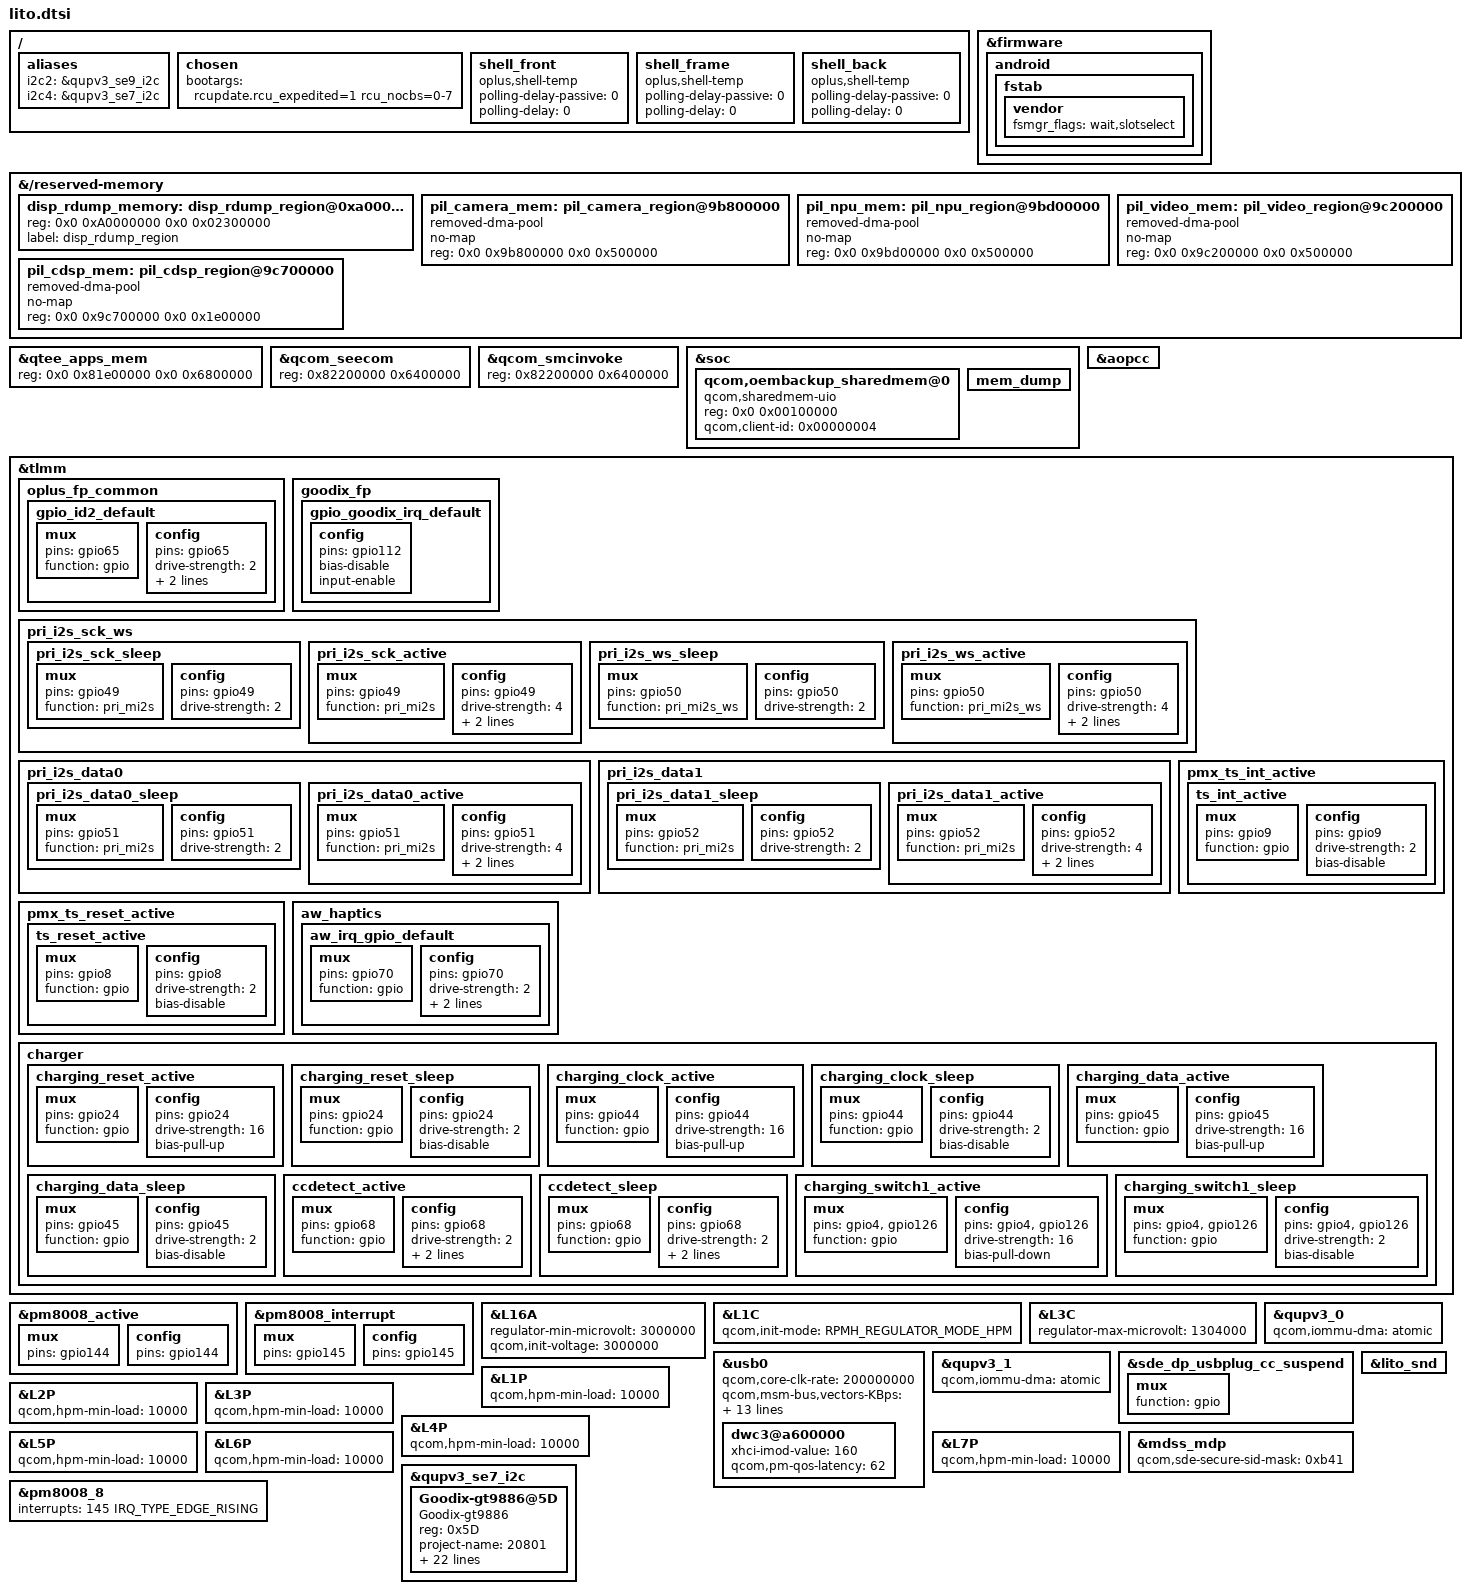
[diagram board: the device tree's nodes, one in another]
// lito.dtsi - OnePlus Nord (20801) delta on top of ../qcom/lito.dtsi
/ {
	aliases {
		i2c2 = &qupv3_se9_i2c;
		i2c4 = &qupv3_se7_i2c;
	};

	chosen {
		bootargs = "rcupdate.rcu_expedited=1 rcu_nocbs=0-7";
	};

	// lito-thermal.dtsi
	shell_front {
		polling-delay-passive = <0>;
		polling-delay = <0>;
		compatible = "oplus,shell-temp";
	};

	shell_frame {
		polling-delay-passive = <0>;
		polling-delay = <0>;
		compatible = "oplus,shell-temp";
	};

	shell_back {
		polling-delay-passive = <0>;
		polling-delay = <0>;
		compatible = "oplus,shell-temp";
	};
};

&firmware {
	android {
		fstab {
			vendor {
				fsmgr_flags = "wait,slotselect";
			};
		};
	};
};

reserved_memory: &{/reserved-memory} {
	disp_rdump_memory: disp_rdump_region@0xa0000000 {
		reg = <0x0 0xA0000000 0x0 0x02300000>;
		label = "disp_rdump_region";
	};
};

/delete-node/ &reserved_xbl_uefi_log;
/delete-node/ &pil_camera_mem;
/delete-node/ &pil_npu_mem;
/delete-node/ &pil_video_mem;
/delete-node/ &pil_cdsp_mem;

&reserved_memory {
	pil_camera_mem: pil_camera_region@9b800000 {
		compatible = "removed-dma-pool";
		no-map;
		reg = <0x0 0x9b800000 0x0 0x500000>;
	};

	pil_npu_mem: pil_npu_region@9bd00000 {
		compatible = "removed-dma-pool";
		no-map;
		reg = <0x0 0x9bd00000 0x0 0x500000>;
	};

	pil_video_mem: pil_video_region@9c200000 {
		compatible = "removed-dma-pool";
		no-map;
		reg = <0x0 0x9c200000 0x0 0x500000>;
	};

	pil_cdsp_mem: pil_cdsp_region@9c700000 {
		compatible = "removed-dma-pool";
		no-map;
		reg = <0x0 0x9c700000 0x0 0x1e00000>;
	};
};

&qtee_apps_mem {
	reg = <0x0 0x81e00000 0x0 0x6800000>;
};

&qcom_seecom {
	reg = <0x82200000 0x6400000>;
};

&qcom_smcinvoke {
	reg = <0x82200000 0x6400000>;
};

&soc {
	//#ifdef FEATURE_OPLUS_NV_BACKUP
	qcom,oembackup_sharedmem@0 {
		compatible = "qcom,sharedmem-uio";
		reg = <0x0 0x00100000>;
		reg-names = "oembackup";
		qcom,client-id = <0x00000004>;
	};

	mem_dump {
		/delete-node/ osm_reg;
		/delete-node/ pcu_reg;
		/delete-node/ fsm_data;
	};
};

&aopcc {
	/delete-property/ qcom,clk-stop-bimc-log;
};

// lito-pinctrl.dtsi
/delete-node/ &spkr_1_sd_n_sleep;
/delete-node/ &spkr_1_sd_n_active;
/delete-node/ &spkr_2_sd_n_sleep;
/delete-node/ &spkr_2_sd_n_active;

&tlmm {
	/delete-node/ spkr_1_sd_n;
	/delete-node/ spkr_2_sd_n;

		oplus_fp_common{
				gpio_id2_default: gpio_id2_default {
						mux {
								pins = "gpio65";
								function = "gpio";
						};
						config {
								pins = "gpio65";
								drive-strength = <2>;
								bias-pull-up;
								input-enable;
					   };
				};
		};

		goodix_fp{
				gpio_goodix_irq_default: gpio_goodix_irq_default {
						/*mux {
								pins = "gpio112";
								function = "gpio";
						};*/
						config {
								pins = "gpio112";
								//drive-strength = <2>;
								bias-disable;
								input-enable;
						};
				};
		};

		pri_i2s_sck_ws {
			pri_i2s_sck_sleep: pri_i2s_sck_sleep {
				mux {
					pins = "gpio49";
					function = "pri_mi2s";
				};

				config {
					pins = "gpio49";
					drive-strength = <2>;   /* 2 mA */
				};
			};

			pri_i2s_sck_active: pri_i2s_sck_active {
				mux {
					pins = "gpio49";
					function = "pri_mi2s";
				};

				config {
					pins = "gpio49";
					drive-strength = <4>;   /* 4 mA */
					bias-disable;
					output-high;
				};
			};

			pri_i2s_ws_sleep: pri_i2s_ws_sleep {
				mux {
					pins = "gpio50";
					function = "pri_mi2s_ws";
				};

				config {
					pins = "gpio50";
					drive-strength = <2>;   /* 2 mA */
				};
			};

			pri_i2s_ws_active: pri_i2s_ws_active {
				mux {
					pins = "gpio50";
					function = "pri_mi2s_ws";
				};

				config {
					pins = "gpio50";
					drive-strength = <4>;   /* 4 mA */
					bias-disable;
					output-high;
				};
			};
		};

		pri_i2s_data0 {
			pri_i2s_data0_sleep: pri_i2s_data0_sleep {
				mux {
					pins = "gpio51";
					function = "pri_mi2s";
				};

				config {
					pins = "gpio51";
					drive-strength = <2>;   /* 2 mA */
				};
			};

			pri_i2s_data0_active: pri_i2s_data0_active {
				mux {
					pins = "gpio51";
					function = "pri_mi2s";
				};

				config {
					pins = "gpio51";
					drive-strength = <4>;   /* 4 mA */
					bias-disable;
					output-high;
				};
			};
		};

		pri_i2s_data1 {
			pri_i2s_data1_sleep: pri_i2s_data1_sleep {
				mux {
					pins = "gpio52";
					function = "pri_mi2s";
				};

				config {
					pins = "gpio52";
					drive-strength = <2>;   /* 2 mA */
				};
			};

			pri_i2s_data1_active: pri_i2s_data1_active {
				mux {
					pins = "gpio52";
					function = "pri_mi2s";
				};

				config {
					pins = "gpio52";
					drive-strength = <4>;   /* 4 mA */
					bias-disable;
					output-high;
				};
			};
		};

		pmx_ts_int_active {
			ts_int_active: ts_int_active {
				mux {
					pins = "gpio9";
					function = "gpio";
				};

				config {
					pins = "gpio9";
					drive-strength = <2>;
					bias-disable;
				};
			};
		};

		pmx_ts_reset_active {
			ts_reset_active: ts_reset_active {
				mux {
					pins = "gpio8";
					function = "gpio";
				};

				config {
					pins = "gpio8";
					drive-strength = <2>;
					bias-disable;
				};
			};
		};

		aw_haptics: aw_haptics {
			aw_irq_gpio_default: aw_irq_gpio_default {
				mux {
					pins = "gpio70";
					function = "gpio";
				};

				config {
					pins = "gpio70";
					drive-strength = <2>;
					input-enable;
					bias-pull-up; /*PULL UP*/
					//bias-disable;
				};
			};
		};

		charger: charger {
			charging_reset_active: charging_reset_active {
				mux {
					pins = "gpio24";
					function = "gpio";
				};

				config {
					pins = "gpio24";
					drive-strength = <16>;
					bias-pull-up;
				};
			};

			charging_reset_sleep: charging_reset_sleep {
				mux {
					pins = "gpio24";
					function = "gpio";
				};

				config {
					pins = "gpio24";
					drive-strength = <2>;
					bias-disable;
					//bias-pull-down;
				};
			};

			charging_clock_active: charging_clock_active {
				mux {
					pins = "gpio44";
					function = "gpio";
				};

				config {
					pins = "gpio44";
					drive-strength = <16>;
					bias-pull-up;
				};
			};

			charging_clock_sleep: charging_clock_sleep {
				mux {
					pins = "gpio44";
					function = "gpio";
				};

				config {
					pins = "gpio44";
					drive-strength = <2>;
					bias-disable;
					//bias-pull-down;
				};
			};

			charging_data_active: charging_data_active {
				mux {
					pins = "gpio45";
					function = "gpio";
				};

				config {
					pins = "gpio45";
					drive-strength = <16>;
					bias-pull-up;
				};
			};

			charging_data_sleep: charging_data_sleep {
				mux {
					pins = "gpio45";
					function = "gpio";
				};

				config {
					pins = "gpio45";
					drive-strength = <2>;
					bias-disable;
					//bias-pull-down;
				};
			};

			ccdetect_active: ccdetect_active {
				mux {
					pins = "gpio68";
					function = "gpio";
				};

				config {
					pins = "gpio68";
					drive-strength = <2>;
					input-enable;
					bias-pull-up; /*PULL UP*/
					//bias-disable;
				};
			};

			ccdetect_sleep: ccdetect_sleep {
				mux {
					pins = "gpio68";
					function = "gpio";
				};

				config {
					pins = "gpio68";
					drive-strength = <2>;
					//output-low;
					//bias-pull-down; /*PULL DOWN*/
					input-enable;
					bias-disable;
				};
			};

			charging_switch1_active: charging_switch1_active {
				mux {
					pins = "gpio4", "gpio126";
					function = "gpio";
				};

				config {
					pins = "gpio4", "gpio126";
					drive-strength = <16>;
					bias-pull-down;
				};
			};

			charging_switch1_sleep: charging_switch1_sleep {
				mux {
					pins = "gpio4", "gpio126";
					function = "gpio";
				};

				config {
					pins = "gpio4", "gpio126";
					drive-strength = <2>;
					bias-disable;
				};
			};
		};

};

&pm8008_active {
	mux {
		pins = "gpio144";
	};

	config {
		pins = "gpio144";
	};
};

&pm8008_interrupt {
	mux {
		pins = "gpio145";
	};

	config {
		pins = "gpio145";
	};
};

// lito-regulators.dtsi
&L16A {
	regulator-min-microvolt = <3000000>;
	qcom,init-voltage = <3000000>;
};

&L1C {
	qcom,init-mode = <RPMH_REGULATOR_MODE_HPM>;
};

&L3C {
	regulator-max-microvolt = <1304000>;
};

// lito-usb.dtsi
&usb0 {
	qcom,core-clk-rate = <200000000>;
	qcom,msm-bus,vectors-KBps =
		/*  suspend vote */
		<MSM_BUS_MASTER_USB3 MSM_BUS_SLAVE_EBI_CH0 0 0>,
		<MSM_BUS_MASTER_USB3 MSM_BUS_SLAVE_IPA_CFG 0 0>,
		<MSM_BUS_MASTER_AMPSS_M0 MSM_BUS_SLAVE_USB3 0 0>,
		/*  nominal vote */
		<MSM_BUS_MASTER_USB3
			MSM_BUS_SLAVE_EBI_CH0 2500000 2500000>,
		<MSM_BUS_MASTER_USB3 MSM_BUS_SLAVE_IPA_CFG 2400 2400>,
		<MSM_BUS_MASTER_AMPSS_M0 MSM_BUS_SLAVE_USB3 40000 40000>,
		/*  svs vote */
		<MSM_BUS_MASTER_USB3
			MSM_BUS_SLAVE_EBI_CH0 2500000 2500000>,
		<MSM_BUS_MASTER_USB3 MSM_BUS_SLAVE_IPA_CFG 2400 2400>,
		<MSM_BUS_MASTER_AMPSS_M0 MSM_BUS_SLAVE_USB3 40000 40000>,
		/*  min vote */
		<MSM_BUS_MASTER_USB3 MSM_BUS_SLAVE_EBI_CH0 1 1>,
		<MSM_BUS_MASTER_USB3 MSM_BUS_SLAVE_IPA_CFG 1 1>,
		<MSM_BUS_MASTER_AMPSS_M0 MSM_BUS_SLAVE_USB3 1 1>;
	qcom,default-bus-vote = <1>; /* use nominal bus voting */

	dwc3@a600000 {
		xhci-imod-value = <160>;
		qcom,pm-qos-latency = <62>;
	};
};

// lito-qupv3.dtsi
&qupv3_0 {
	qcom,iommu-dma = "atomic";
};

&qupv3_1 {
	qcom,iommu-dma = "atomic";
};

// lito-pinctrl.dtsi: missing function name
&sde_dp_usbplug_cc_suspend {
	mux {
		function = "gpio";
	};
};

// lito-audio.dtsi
&lito_snd {
	/delete-property/ fsa4480-i2c-handle;
};

// msm-audio-lpass.dtsi: Nord has no SLIMbus DAIs
/delete-node/ &sb_0_rx;
/delete-node/ &sb_0_tx;
/delete-node/ &sb_1_rx;
/delete-node/ &sb_1_tx;
/delete-node/ &sb_2_rx;
/delete-node/ &sb_2_tx;
/delete-node/ &sb_3_rx;
/delete-node/ &sb_3_tx;
/delete-node/ &sb_4_rx;
/delete-node/ &sb_4_tx;
/delete-node/ &sb_5_rx;
/delete-node/ &sb_5_tx;
/delete-node/ &sb_6_rx;
/delete-node/ &sb_8_rx;

// pm8008.dtsi
&L1P { qcom,hpm-min-load = <10000>; };
&L2P { qcom,hpm-min-load = <10000>; };
&L3P { qcom,hpm-min-load = <10000>; };
&L4P { qcom,hpm-min-load = <10000>; };
&L5P { qcom,hpm-min-load = <10000>; };
&L6P { qcom,hpm-min-load = <10000>; };
&L7P { qcom,hpm-min-load = <10000>; };

// lito-sde.dtsi
&mdss_mdp {
	qcom,sde-secure-sid-mask = <0xb41>;
};

&qupv3_se7_i2c {
        status = "ok";
	Goodix-gt9886@5D {
		compatible = "Goodix-gt9886";
		reg = <0x5D>;
		project-name = "20801";
		chip-name = "GT885";
		module_id = <7>;
		/* Interrupt && Irq-gpio */
		interrupt-parent = <&tlmm>;
		interrupts = <9 0x2002>;

		/* Power Config */
		vdd_2v8-supply = <&pm8150_l13>;
		//vcc_1v8-supply = <&pm8150a_l1>;
		vdd_2v8_volt = <3008000>;

		/* Other HW Resource */
		irq-gpio = <&tlmm 9 0x2002>;
		reset-gpio = <&tlmm 8 0x1>;
		pinctrl-names = "pin_set_high", "pin_set_low";
		pinctrl-0 = <&ts_int_active &ts_reset_active>;
		pinctrl-1 = <&ts_reset_suspend>;

		touchpanel,max-num-support = <10>;
		touchpanel,tx-rx-num = <15 34>;
		touchpanel,panel-coords = <1080 2400>;
		touchpanel,display-coords = <1080 2400>;

		/* SW Support Feature Control */
		black_gesture_support = <1>;
		//fw_edge_limit_support;
		//charger_pump_support;
		//spurious_fingerprint_support;
		//fw_update_app_support;
		//smart_gesture_support;
		//game_switch_support = <1>;
		face_detect_support = <1>;
		lcd_refresh_rate_switch = <1>;
		touch_hold_support = <1>;
		charge_detect_support = <1>;
		register-is-16bit = <1>;
		//module_id_support = <1>;
		//kernel_grip_support;
		//health_monitor_support;
		//fingerprint_underscreen_support;
		//headset_pump_support;
		//pressure_report_support;

		/*
		 *Virtual Key Config:
		 *1:touchpanel,button-type: <virtualkey_type  supportted_button-map>
		 *virtualkey_type:
		*Type 1: using board_properties
		 *Type 2: using same IC (button zone&& touch zone are seprate)
		 *Type 3: using diffrent IC (button zone&& touch zone are seprate)
		 *Type 4: No need of virtual key process
		 *supportted_button-map:select|menu|home|back
		 *
		 *2:touchpanel,button-map
		 *type (X1,Y1)(X2,Y2)(X3,Y3)(Width_X,Hight_Y)--Only when button-type is 0
		 */
		touchpanel,button-type = <4 0x00>;
		touchpanel.button-TRx = <0 0>;
	 };
};

&pm8008_8 {
	interrupts = <145 IRQ_TYPE_EDGE_RISING>;
};
